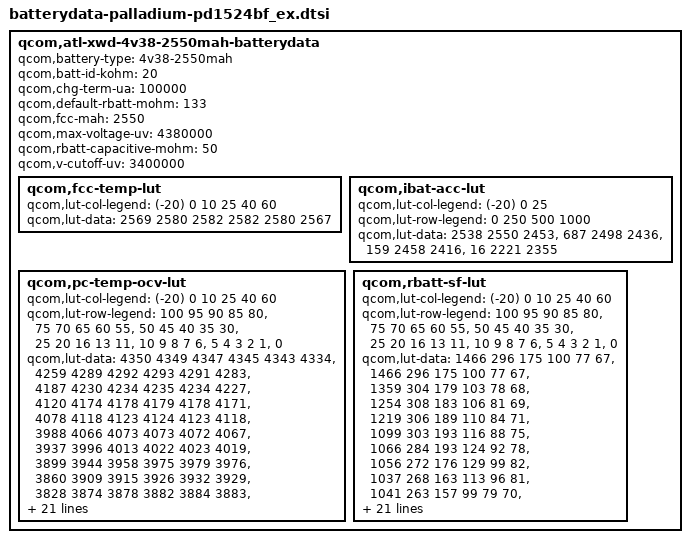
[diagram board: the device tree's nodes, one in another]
/* Copyright (c) 2013-2014, The Linux Foundation. All rights reserved.
 *
 * This program is free software; you can redistribute it and/or modify
 * it under the terms of the GNU General Public License version 2 and
 * only version 2 as published by the Free Software Foundation.
 *
 * This program is distributed in the hope that it will be useful,
 * but WITHOUT ANY WARRANTY; without even the implied warranty of
 * MERCHANTABILITY or FITNESS FOR A PARTICULAR PURPOSE.  See the
 * GNU General Public License for more details.
 */
qcom,atl-xwd-4v38-2550mah-batterydata {
	qcom,battery-type = "4v38-2550mah";
	qcom,batt-id-kohm = <20>;
	qcom,chg-term-ua = <100000>;
	qcom,default-rbatt-mohm = <133>;
	qcom,fcc-mah = <2550>;
	qcom,max-voltage-uv = <4380000>;
	qcom,rbatt-capacitive-mohm = <50>;
	qcom,v-cutoff-uv = <3400000>;

	qcom,fcc-temp-lut {
		qcom,lut-col-legend = <(-20) 0 10 25 40 60>;
		qcom,lut-data = <2569 2580 2582 2582 2580 2567>;
	};

	qcom,ibat-acc-lut {
		qcom,lut-col-legend = <(-20) 0 25>;
		qcom,lut-row-legend = <0 250 500 1000>;
		qcom,lut-data = <2538 2550 2453>,
				<687 2498 2436>,
				<159 2458 2416>,
				<16 2221 2355>;
	};
	qcom,pc-temp-ocv-lut {
		qcom,lut-col-legend = <(-20) 0 10 25 40 60>;
		qcom,lut-row-legend = <100 95 90 85 80>,
					<75 70 65 60 55>,
					<50 45 40 35 30>,
					<25 20 16 13 11>,
					<10 9 8 7 6>,
					<5 4 3 2 1>,
					<0>;
		qcom,lut-data = <4350 4349 4347 4345 4343 4334>,
				<4259 4289 4292 4293 4291 4283>,
				<4187 4230 4234 4235 4234 4227>,
				<4120 4174 4178 4179 4178 4171>,
				<4078 4118 4123 4124 4123 4118>,
				<3988 4066 4073 4073 4072 4067>,
				<3937 3996 4013 4022 4023 4019>,
				<3899 3944 3958 3975 3979 3976>,
				<3860 3909 3915 3926 3932 3929>,
				<3828 3874 3878 3882 3884 3883>,
				<3809 3843 3848 3850 3852 3851>,
				<3793 3818 3823 3825 3827 3827>,
				<3779 3796 3802 3805 3807 3806>,
				<3765 3779 3784 3788 3790 3789>,
				<3751 3768 3771 3773 3772 3764>,
				<3738 3755 3759 3757 3750 3739>,
				<3722 3738 3742 3738 3731 3717>,
				<3708 3719 3721 3717 3710 3696>,
				<3694 3706 3703 3698 3692 3680>,
				<3682 3698 3695 3690 3684 3672>,
				<3676 3695 3692 3689 3682 3671>,
				<3668 3691 3691 3688 3681 3670>,
				<3658 3688 3689 3686 3680 3668>,
				<3646 3684 3687 3684 3677 3664>,
				<3629 3677 3680 3677 3668 3651>,
				<3606 3658 3658 3652 3642 3619>,
				<3574 3616 3613 3605 3597 3572>,
				<3525 3555 3552 3544 3538 3511>,
				<3450 3472 3469 3462 3459 3429>,
				<3313 3345 3343 3338 3340 3300>,
				<3000 3044 3023 3000 3000 3060>;
	};

	qcom,rbatt-sf-lut {
		qcom,lut-col-legend = <(-20) 0 10 25 40 60>;
		qcom,lut-row-legend = <100 95 90 85 80>,
					<75 70 65 60 55>,
					<50 45 40 35 30>,
					<25 20 16 13 11>,
					<10 9 8 7 6>,
					<5 4 3 2 1>,
					<0>;
		qcom,lut-data = <1466 296 175 100 77 67>,
				<1466 296 175 100 77 67>,
				<1359 304 179 103 78 68>,
				<1254 308 183 106 81 69>,
				<1219 306 189 110 84 71>,
				<1099 303 193 116 88 75>,
				<1066 284 193 124 92 78>,
				<1056 272 176 129 99 82>,
				<1037 268 163 113 96 81>,
				<1041 263 157 99 79 70>,
				<1071 263 157 97 76 67>,
				<1110 265 160 98 78 70>,
				<1149 265 162 102 82 73>,
				<1207 270 163 106 86 76>,
				<1273 285 168 106 84 71>,
				<1362 302 174 103 78 69>,
				<1465 320 178 103 78 68>,
				<1563 331 180 103 79 68>,
				<1632 349 179 100 76 68>,
				<1650 367 182 100 77 68>,
				<1615 374 184 102 79 69>,
				<1545 356 182 103 80 71>,
				<1607 372 187 106 83 73>,
				<1673 387 196 112 86 74>,
				<1743 408 203 114 85 73>,
				<1851 417 201 106 81 69>,
				<2090 426 200 105 80 70>,
				<2571 475 212 109 82 73>,
				<3474 547 236 117 88 80>,
				<6948 678 284 141 111 153>,
				<6948 678 284 141 111 153>;//<13896 1355 569 283 222 306>;
	};
};

